AUTOSAR XML (schema 00046)
standard types defined: boolean, uint8, uint16, uint32, float32, boolean_DataConstr, boolean_CompuMethod
package /PortInterfaces
  5 x sender receiver interface:
    LockCmd
      data LockCmd: type=uint8
    LockReq
      data LockReq: type=uint8
    VehSpd
      data VehSpd: type=uint16
    FrLeDoorSts
      data FrLeDoorSts: type=uint8
    ReLeDoorSts
      data ReLeDoorSts: type=uint8
  client server interface SetDoorCmd
    operation DoorMethod
      arg doorId: type=uint8, direction=IN, server-argument-impl-policy=USE-ARGUMENT-TYPE
      arg doorCmd: type=DoorStatus_T, direction=IN, server-argument-impl-policy=USE-ARGUMENT-TYPE
      arg result: type=uint8, direction=OUT, server-argument-impl-policy=USE-ARGUMENT-TYPE
  client server interface SetSeatCmd
    operation SeatMethod
      arg seatPos: type=uint16, direction=IN, server-argument-impl-policy=USE-ARGUMENT-TYPE
      arg status: type=boolean, direction=OUT, server-argument-impl-policy=USE-ARGUMENT-TYPE
  client server interface CSwindowCmd
    operation method1
      arg winId: type=uint8, direction=IN, server-argument-impl-policy=USE-ARGUMENT-TYPE
      arg result: type=uint8, direction=OUT, server-argument-impl-policy=USE-ARGUMENT-TYPE
    operation method2
      arg winPos: type=uint16, direction=IN, server-argument-impl-policy=USE-ARGUMENT-TYPE
      arg winCmd: type=uint8, direction=IN, server-argument-impl-policy=USE-ARGUMENT-TYPE
      arg result: type=uint8, direction=OUT, server-argument-impl-policy=USE-ARGUMENT-TYPE
  sender receiver interface DoorStsIf
    data DoorSts: type=DoorStatus_T
package /Constants
  6 x constant specification:
    LockCmd_IV: value-spec=0
    LockReq_IV: value-spec=0
    VehSpd_IV: value-spec=0
    FrLeDoorSts_IV: value-spec=0
    ReLeDoorSts_IV: value-spec=0
    DoorSts_IV: value-spec=fields=[Position:0, LockSts:0, Speed:0]
package /AUTOSAR_Platform/ImplementationDataTypes
  impl type DoorStatus_T: category=STRUCTURE
    element Position: implementation-data-type=uint8
    element LockSts: implementation-data-type=boolean
    element Speed: implementation-data-type=uint16
  impl type VehicleInfo_T: category=STRUCTURE
    element VehSpd: implementation-data-type=float32
    element DoorInfo: implementation-data-type=DoorStatus_T
package /ComponentTypes
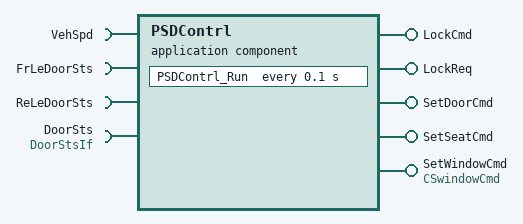
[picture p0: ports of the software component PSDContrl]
  application sw component type PSDContrl
    provide port LockCmd: nonqueued-sender-com-spec{data-element=LockCmd, init-value=constant-reference=LockCmd_IV}, provided-interface=LockCmd
    provide port LockReq: nonqueued-sender-com-spec{data-element=LockReq, init-value=constant-reference=LockReq_IV}, provided-interface=LockReq
    require port VehSpd: nonqueued-receiver-com-spec{data-element=VehSpd, init-value=constant-reference=VehSpd_IV}, required-interface=VehSpd
    require port FrLeDoorSts: nonqueued-receiver-com-spec{data-element=FrLeDoorSts, init-value=constant-reference=FrLeDoorSts_IV}, required-interface=FrLeDoorSts
    require port ReLeDoorSts: nonqueued-receiver-com-spec{data-element=ReLeDoorSts, init-value=constant-reference=ReLeDoorSts_IV}, required-interface=ReLeDoorSts
    provide port SetDoorCmd: server-com-spec=DoorMethod, provided-interface=SetDoorCmd
    provide port SetSeatCmd: server-com-spec=SeatMethod, provided-interface=SetSeatCmd
    provide port SetWindowCmd: provided-com-specs=[method1, method2, method2], provided-interface=CSwindowCmd
    require port DoorSts: nonqueued-receiver-com-spec{data-element=DoorSts, init-value=constant-reference=DoorSts_IV}, required-interface=DoorStsIf
    behavior PSDContrl_InternalBehavior
      exclusive area ExampleExclusiveArea
      init event IT_PSDContrl_Init: start-on-event=PSDContrl_Init
      timing event TMT_PSDContrl_Run: start-on-event=PSDContrl_Run, period=0.1
      5 x operation invoked event:
        OIT_PSDContrl_SetDoorCmd_DoorMethod_SetDoorCmd_DoorMethod: start-on-event=PSDContrl_SetDoorCmd_DoorMethod, operation=SetDoorCmd.DoorMethod
        OIT_PSDContrl_SetSeatCmd_SeatMethod_SetSeatCmd_SeatMethod: start-on-event=PSDContrl_SetSeatCmd_SeatMethod, operation=SetSeatCmd.SeatMethod
        OIT_PSDContrl_SetWindowCmd_method1_SetWindowCmd_method1: start-on-event=PSDContrl_SetWindowCmd_method1, operation=SetWindowCmd.method1
        OIT_PSDContrl_SetWindowCmd_method2_SetWindowCmd_method2_0: start-on-event=PSDContrl_InternalBehavior/PSDContrl_SetWindowCmd_method2, operation=SetWindowCmd.method2
        OIT_PSDContrl_SetWindowCmd_method2_SetWindowCmd_method2_1: start-on-event=PSDContrl_InternalBehavior/PSDContrl_SetWindowCmd_method2, operation=SetWindowCmd.method2
      port-api-options:
        enable-take-address=false, indirect-api=false, port=DoorSts
        enable-take-address=false, indirect-api=false, port=FrLeDoorSts
        enable-take-address=false, indirect-api=false, port=LockCmd
        enable-take-address=false, indirect-api=false, port=LockReq
        enable-take-address=false, indirect-api=false, port=ReLeDoorSts
        enable-take-address=false, indirect-api=false, port=SetDoorCmd
        enable-take-address=false, indirect-api=false, port=SetSeatCmd
        enable-take-address=false, indirect-api=false, port=SetWindowCmd
        enable-take-address=false, indirect-api=false, port=VehSpd
      7 x runnable:
        PSDContrl_Init
        PSDContrl_Run
          data-receive-point-by-arguments:
            4 x access:
              REC_VehSpd_VehSpd: accessed-variable=VehSpd.VehSpd
              REC_FrLeDoorSts_FrLeDoorSts: accessed-variable=FrLeDoorSts.FrLeDoorSts
              REC_ReLeDoorSts_ReLeDoorSts: accessed-variable=ReLeDoorSts.ReLeDoorSts
              REC_DoorSts_DoorSts: accessed-variable=DoorSts.DoorSts
          data-send-points:
            access SEND_LockCmd_LockCmd: accessed-variable=LockCmd.LockCmd
            access SEND_LockReq_LockReq: accessed-variable=LockReq.LockReq
        PSDContrl_SetDoorCmd_DoorMethod
        PSDContrl_SetSeatCmd_SeatMethod
        PSDContrl_SetWindowCmd_method1
        PSDContrl_SetWindowCmd_method2
        PSDContrl_SetWindowCmd_method2
  swc implementation PSDContrl_Implementation: behavior=PSDContrl_InternalBehavior
